# ATA5782 device description
Architecture: AVR8; Family: megaAVR
Registers are 8-bit, access not given, no defined reset value unless marked. A register's access mark holds for its fields unless they carry their own. Offsets are from the block's base; [hi:lo] are bit positions; {n}, {i} and the like mark numbered series.

## SFIFO
Instances: SFIFO 0x00
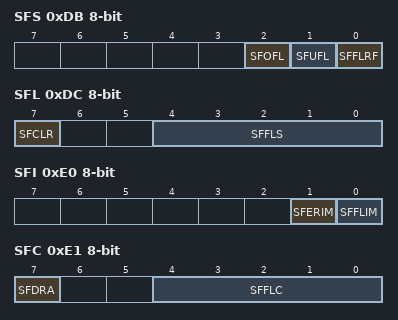
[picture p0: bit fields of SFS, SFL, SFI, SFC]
0xDB SFS — Support FIFO Status Register
  [2] SFOFL — Support FIFO Overflow Flag
  [1] SFUFL — Support FIFO Underflow Flag
  [0] SFFLRF — Support FIFO Fill-Level Reached Status Flag
0xDC SFL — Support FIFO Fill Level Register
  [7] SFCLR — Support FIFO Clear
  [4:0] SFFLS — Support FIFO Fill Level Status
0xDD SFWP — Support FIFO Write Pointer
  [4:0] SFWP
0xDE SFRP — Support FIFO Read Pointer
  [4:0] SFRP
0xDF SFD — Support FIFO Data Register
0xE0 SFI — Support FIFO Interrupt Mask Register
  [1] SFERIM — Support FIFO Error Interrupt Mask
  [0] SFFLIM — Support FIFO Fill-level Interrupt Mask
0xE1 SFC — Support FIFO Configuration Register
  [7] SFDRA — Support FIFO Direct Read Access Operational Mode
  [4:0] SFFLC — Support FIFO Fill-Level Configuration

## SPI
Instances: SPI 0x00
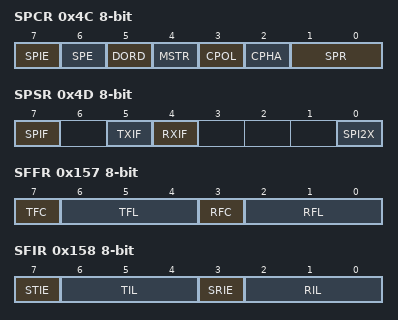
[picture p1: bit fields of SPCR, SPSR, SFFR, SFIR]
0x4C SPCR — SPI Control Register
  [7] SPIE — SPI Interrupt Enable
  [6] SPE — SPI Enable
  [5] DORD — Data Order
  [4] MSTR — Master/Slave Select
  [3] CPOL — Clock polarity
  [2] CPHA — Clock Phase
  [1:0] SPR — SPI Clock Rate Selects
    0=clkio/4; 1=clkio/16; 2=clkio/64; 3=clkio/128; 4=clkio/2; 5=clkio/8; 6=clkio/32; 7=clkio/64
0x4D SPSR — SPI Status Register
  [7] SPIF — SPI Interrupt Flag
  [5] TXIF — Tx Buffer Interrupt Flag
  [4] RXIF — Rx Buffer Interrupt Flag
  [0] SPI2X — Double SPI Speed Bit
0x4E SPDR — SPI Data Register
0x157 SFFR — SPI FIFO Fill Status Register
  [7] TFC — SPI Tx Buffer Clear
  [6:4] TFL — SPI Transmit Buffer Fill Level
  [3] RFC — SPI Rx Buffer Clear
  [2:0] RFL — SPI Receive Buffer Fill Level
0x158 SFIR — SPI FIFO Interrupt Register
  [7] STIE — SPI Tx Buffer Interrupt Enable
  [6:4] TIL — SPI Transmit Buffer Interrupt Level
  [3] SRIE — SPI Rx Buffer Interrupt Enable
  [2:0] RIL — SPI Receive Buffer Interrupt Level

## SUP
Instances: SUP 0x00
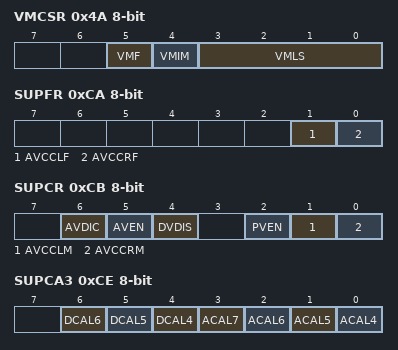
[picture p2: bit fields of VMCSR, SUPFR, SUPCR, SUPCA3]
0x4A VMCSR — Voltage Monitor Control and Status Register
  [5] VMF — Voltage Monitor Flag
  [4] VMIM — Voltage Monitor Interrupt Mask
  [3:0] VMLS — Voltage Monitor Level Select
0xCA SUPFR — Supply Interrupt Flag Register
  [1] AVCCLF — AVCC low interrupt flag
  [0] AVCCRF — AVCC reset interrupt flag
0xCB SUPCR — Supply Control Register
  [6] AVDIC — AVCC Double Internal Current
  [5] AVEN — AVCC Enable
  [4] DVDIS — DVCC Disable
  [2] PVEN — Power amplifier Voltage supply Enable
  [1] AVCCLM — AVCC Low Interrupt Mask Bit
  [0] AVCCRM — AVCC Reset Interrupt Mask Bit
0xCD SUPCA2 — Supply calibration register 2
  [3:0] BGCAL — Band Gap Calibration
0xCE SUPCA3 — Supply calibration register 3
  [6] DCAL6 — DVCC Reset Threshold Calibration bit 6
  [5] DCAL5 — DVCC Reset Threshold Calibration bit 5
  [4] DCAL4 — DVCC Reset Threshold Calibration bit 4
  [n-4] ACAL{n} (n=4..7) — AVCC Reset Threshold Calibration bit {n}
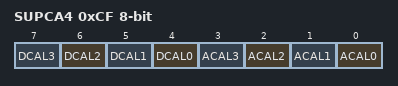
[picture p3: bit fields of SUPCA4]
0xCF SUPCA4 — Supply calibration register 4
  [n+4] DCAL{n} (n=0..3) — DVCC Regulator Output Voltage Calibration bit {n}
  [n] ACAL{n} (n=0..3) — AVCC Regulator Output Voltage Calibration bit {n}
0xD0 CALRDY — Calibration ready signature
0xD1 VMCAL — Voltage Monitor Calibration register
  [2:0] VMCAL — Voltage monitor calibration

## SYMCH
Instances: SYMCH 0x00
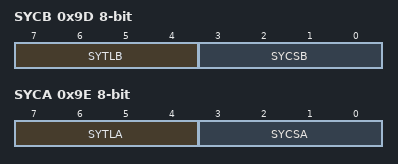
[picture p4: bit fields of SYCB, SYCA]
0x9D SYCB — Symbol check configuration for data path B
  [7:4] SYTLB — Symbol timing limit for path B
  [3:0] SYCSB — Symbol Check check size for data path B
0x9E SYCA — Symbol check configuration for data path A
  [7:4] SYTLA — Symbol timing limit for path A
  [3:0] SYCSA — Symbol Check check size for data path A

## TEMPER
Instances: TEMPER 0x00
0x9B TEMPL — Temperature Low byte
0x9C TEMPH — Temperature High byte

## TIMER0_WDT
Instances: TIMER0_WDT 0x00
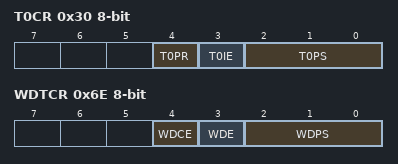
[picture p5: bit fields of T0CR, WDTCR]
0x30 T0CR — Timer0 Control Register
  [4] T0PR — Timer 0 Prescaler Reset
  [3] T0IE — Timer 0 Interrupt Enable
  [2:0] T0PS — Timer 0 Prescaler Select
0x4F T0IFR — Timer0 Interrupt Flag Register
  [0] T0F — Timer0 Flag
0x6E WDTCR — Watchdog Timer0 control Register
  [4] WDCE — Watchdog Change Enable
  [3] WDE — Watchdog System Reset Enable
  [2:0] WDPS — Watchdog Prescaler Select
